VERSION "1.1"

NS_ :

BS_:
BU_:

CM_ "CZONE Proprietary MSG DBC File
Author: Dominique Parolin and some other random GUY !
for Winnebago Industries Inc.
";

CM_ "80ff0400 Used for just the PGN portion for all devices and priorities";
BO_ 2164196352 Heartbeat: 8 Vector__XXX
    SG_ Manufacturer_Code: 0|16@1+ (1,0)   [0|65535]   "ID"    Vector__XXX
    SG_ Dipswitch: 16|8@1+ (1,0)   [0|255]     "DIP"   Vector__XXX
    SG_ Instance: 24|8@1+ (1,0)   [0|255]     "?"     Vector__XXX
    SG_ Output1: 32|1@1+ (1,0)   [0|1]   "OnOff"     Vector__XXX
    SG_ Output2: 33|1@1+ (1,0)   [0|1]   "OnOff"     Vector__XXX
    SG_ Output3: 34|1@1+ (1,0)   [0|1]   "OnOff"     Vector__XXX
    SG_ Output4: 35|1@1+ (1,0)   [0|1]   "OnOff"     Vector__XXX
    SG_ Output5: 36|1@1+ (1,0)   [0|1]   "OnOff"     Vector__XXX
    SG_ Output6: 37|1@1+ (1,0)   [0|1]   "OnOff"     Vector__XXX
    SG_ Output7: 38|1@1+ (1,0)   [0|1]   "OnOff"     Vector__XXX
    SG_ Output8: 39|1@1+ (1,0)   [0|1]   "OnOff"     Vector__XXX
    SG_ Output9: 40|1@1+ (1,0)   [0|1]   "OnOff"     Vector__XXX
    SG_ Output10: 41|1@1+ (1,0)   [0|1]   "OnOff"     Vector__XXX
    SG_ Output11: 42|1@1+ (1,0)   [0|1]   "OnOff"     Vector__XXX
    SG_ Output12: 43|1@1+ (1,0)   [0|1]   "OnOff"     Vector__XXX
    SG_ Output13: 44|1@1+ (1,0)   [0|1]   "OnOff"     Vector__XXX
    SG_ Output14: 45|1@1+ (1,0)   [0|1]   "OnOff"     Vector__XXX
    SG_ Output15: 46|1@1+ (1,0)   [0|1]   "OnOff"     Vector__XXX
    SG_ Output16: 47|1@1+ (1,0)   [0|1]   "OnOff"     Vector__XXX
    SG_ Output17: 48|1@1+ (1,0)   [0|1]   "OnOff"     Vector__XXX
    SG_ Output18: 49|1@1+ (1,0)   [0|1]   "OnOff"     Vector__XXX
    SG_ Output19: 50|1@1+ (1,0)   [0|1]   "OnOff"     Vector__XXX
    SG_ Output20: 51|1@1+ (1,0)   [0|1]   "OnOff"     Vector__XXX
    SG_ Output21: 52|1@1+ (1,0)   [0|1]   "OnOff"     Vector__XXX
    SG_ Output22: 53|1@1+ (1,0)   [0|1]   "OnOff"     Vector__XXX
    SG_ Output23: 54|1@1+ (1,0)   [0|1]   "OnOff"     Vector__XXX
    SG_ Output24: 55|1@1+ (1,0)   [0|1]   "OnOff"     Vector__XXX
    SG_ Output25: 56|1@1+ (1,0)   [0|1]   "OnOff"     Vector__XXX
    SG_ Output26: 57|1@1+ (1,0)   [0|1]   "OnOff"     Vector__XXX
    SG_ Output27: 58|1@1+ (1,0)   [0|1]   "OnOff"     Vector__XXX
    SG_ Output28: 59|1@1+ (1,0)   [0|1]   "OnOff"     Vector__XXX
    SG_ Output29: 60|1@1+ (1,0)   [0|1]   "OnOff"     Vector__XXX
    SG_ Output30: 61|1@1+ (1,0)   [0|1]   "OnOff"     Vector__XXX
    SG_ Output31: 62|1@1+ (1,0)   [0|1]   "OnOff"     Vector__XXX
    SG_ Output32: 63|1@1+ (1,0)   [0|1]   "OnOff"     Vector__XXX

    39207 "BEP Marine";

CM_ "80ff1C00 Used for just the PGN portion for all devices and priorities";
BO_ 2164202496 RvSwitch: 8 Vector__XXX
    SG_ Manufacturer_Code: 0|16@1+ (1,0)   [0|65535]   "ID"    Vector__XXX
    SG_ Dipswitch: 16|8@1+ (1,0)   [0|255]     "DIP"   Vector__XXX
    SG_ Instance: 24|8@1+ (1,0)   [0|255]     "?"     Vector__XXX
    SG_ Output1: 32|1@1+ (1,0)   [0|1]   "OnOff"     Vector__XXX
    SG_ Output2: 33|1@1+ (1,0)   [0|1]   "OnOff"     Vector__XXX
    SG_ Output3: 34|1@1+ (1,0)   [0|1]   "OnOff"     Vector__XXX
    SG_ Output4: 35|1@1+ (1,0)   [0|1]   "OnOff"     Vector__XXX
    SG_ Output5: 36|1@1+ (1,0)   [0|1]   "OnOff"     Vector__XXX
    SG_ Output6: 37|1@1+ (1,0)   [0|1]   "OnOff"     Vector__XXX
    SG_ Output7: 38|1@1+ (1,0)   [0|1]   "OnOff"     Vector__XXX
    SG_ Output8: 39|1@1+ (1,0)   [0|1]   "OnOff"     Vector__XXX
    SG_ Output9: 40|1@1+ (1,0)   [0|1]   "OnOff"     Vector__XXX
    SG_ Output10: 41|1@1+ (1,0)   [0|1]   "OnOff"     Vector__XXX
    SG_ Output11: 42|1@1+ (1,0)   [0|1]   "OnOff"     Vector__XXX
    SG_ Output12:        43|1@1+ (1,0)   [0|1]   "OnOff"     Vector__XXX
    SG_ Output13:        44|1@1+ (1,0)   [0|1]   "OnOff"     Vector__XXX
    SG_ Output14:        45|1@1+ (1,0)   [0|1]   "OnOff"     Vector__XXX
    SG_ Output15:        46|1@1+ (1,0)   [0|1]   "OnOff"     Vector__XXX
    SG_ Output16:        47|1@1+ (1,0)   [0|1]   "OnOff"     Vector__XXX
    SG_ Output17:        48|1@1+ (1,0)   [0|1]   "OnOff"     Vector__XXX
    SG_ Output18:        49|1@1+ (1,0)   [0|1]   "OnOff"     Vector__XXX
    SG_ Output19:        50|1@1+ (1,0)   [0|1]   "OnOff"     Vector__XXX
    SG_ Output20:        51|1@1+ (1,0)   [0|1]   "OnOff"     Vector__XXX
    SG_ Output21:        52|1@1+ (1,0)   [0|1]   "OnOff"     Vector__XXX
    SG_ Output22:        53|1@1+ (1,0)   [0|1]   "OnOff"     Vector__XXX
    SG_ Output23:        54|1@1+ (1,0)   [0|1]   "OnOff"     Vector__XXX
    SG_ Output24:        55|1@1+ (1,0)   [0|1]   "OnOff"     Vector__XXX
    SG_ Output25:        56|1@1+ (1,0)   [0|1]   "OnOff"     Vector__XXX
    SG_ Output26:        57|1@1+ (1,0)   [0|1]   "OnOff"     Vector__XXX
    SG_ Output27:        58|1@1+ (1,0)   [0|1]   "OnOff"     Vector__XXX
    SG_ Output28:        59|1@1+ (1,0)   [0|1]   "OnOff"     Vector__XXX
    SG_ Output29:        60|1@1+  (1,0)   [0|1]   "OnOff"     Vector__XXX
    SG_ Output30:        61|1@1+ (1,0)   [0|1]   "OnOff"     Vector__XXX
    SG_ Output31:        62|1@1+ (1,0)   [0|1]   "OnOff"     Vector__XXX
    SG_ Output32:        63|1@1+ (1,0)   [0|1]   "OnOff"     Vector__XXX

CM_ "80ff1C00 Used for just the PGN portion for all devices and priorities";
    39207 "BEP Marine";

CM_ "80ff1500 ";
BO_ 2164200704 RvOutput: 8 Vector__XXX
    SG_ Manufacturer_Code:        0|16@1+ (1,0)   [0|65535]   "ID"    Vector__XXX
    SG_ Dipswitch:        16|8@1+ (1,0)   [0|255]     "DIP"   Vector__XXX
    SG_ Instance:        24|8@1+ (1,0)   [0|255]     "?"     Vector__XXX
    SG_ Output1:        32|1@1+ (1,0)   [0|1]   "OnOff"     Vector__XXX
    SG_ Output2:        33|1@1+ (1,0)   [0|1]   "OnOff"     Vector__XXX
    SG_ Output3:        34|1@1+ (1,0)   [0|1]   "OnOff"     Vector__XXX
    SG_ Output4:        35|1@1+ (1,0)   [0|1]   "OnOff"     Vector__XXX
    SG_ Output5:        36|1@1+ (1,0)   [0|1]   "OnOff"     Vector__XXX
    SG_ Output6:        37|1@1+ (1,0)   [0|1]   "OnOff"     Vector__XXX
    SG_ Output7:        38|1@1+ (1,0)   [0|1]   "OnOff"     Vector__XXX
    SG_ Output8:        39|1@1+ (1,0)   [0|1]   "OnOff"     Vector__XXX
    SG_ Output9:        40|1@1+ (1,0)   [0|1]   "OnOff"     Vector__XXX
    SG_ Output10:        41|1@1+ (1,0)   [0|1]   "OnOff"     Vector__XXX
    SG_ Output11:        42|1@1+ (1,0)   [0|1]   "OnOff"     Vector__XXX
    SG_ Output12:        43|1@1+ (1,0)   [0|1]   "OnOff"     Vector__XXX
    SG_ Output13:        44|1@1+ (1,0)   [0|1]   "OnOff"     Vector__XXX
    SG_ Output14:        45|1@1+ (1,0)   [0|1]   "OnOff"     Vector__XXX
    SG_ Output15:        46|1@1+ (1,0)   [0|1]   "OnOff"     Vector__XXX
    SG_ Output16:        47|1@1+ (1,0)   [0|1]   "OnOff"     Vector__XXX
    SG_ Output17:        48|1@1+ (1,0)   [0|1]   "OnOff"     Vector__XXX
    SG_ Output18:        49|1@1+ (1,0)   [0|1]   "OnOff"     Vector__XXX
    SG_ Output19:        50|1@1+ (1,0)   [0|1]   "OnOff"     Vector__XXX
    SG_ Output20:        51|1@1+ (1,0)   [0|1]   "OnOff"     Vector__XXX
    SG_ Output21:        52|1@1+ (1,0)   [0|1]   "OnOff"     Vector__XXX
    SG_ Output22:        53|1@1+ (1,0)   [0|1]   "OnOff"     Vector__XXX
    SG_ Output23:        54|1@1+ (1,0)   [0|1]   "OnOff"     Vector__XXX
    SG_ Output24:        55|1@1+ (1,0)   [0|1]   "OnOff"     Vector__XXX
    SG_ Output25:        56|1@1+ (1,0)   [0|1]   "OnOff"     Vector__XXX
    SG_ Output26:        57|1@1+ (1,0)   [0|1]   "OnOff"     Vector__XXX
    SG_ Output27:        58|1@1+ (1,0)   [0|1]   "OnOff"     Vector__XXX
    SG_ Output28:        59|1@1+ (1,0)   [0|1]   "OnOff"     Vector__XXX
    SG_ Output29:        60|1@1+  (1,0)   [0|1]   "OnOff"     Vector__XXX
    SG_ Output30:        61|1@1+ (1,0)   [0|1]   "OnOff"     Vector__XXX
    SG_ Output31:        62|1@1+ (1,0)   [0|1]   "OnOff"     Vector__XXX
    SG_ Output32:        63|1@1+ (1,0)   [0|1]   "OnOff"     Vector__XXX

CM_ "ff1500 Used for just the PGN portion for all devices and priorities";
    39207 "BEP Marine";

CM_ "ff0f00 Czone Alerts";
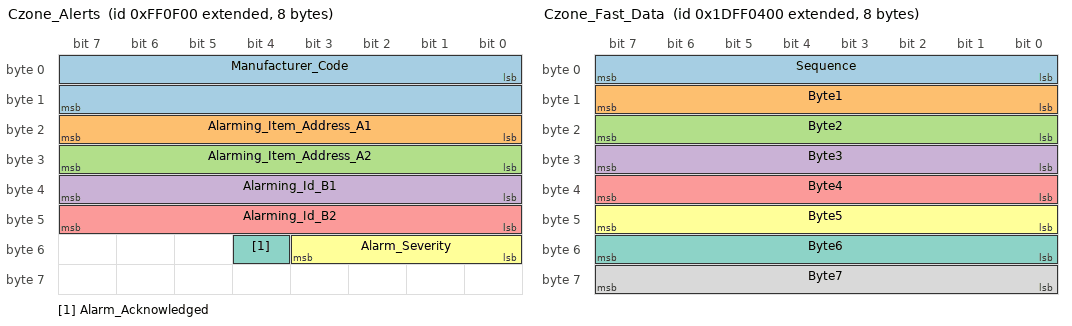
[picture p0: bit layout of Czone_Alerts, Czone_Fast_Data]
BO_ 2164199168 Czone_Alerts: 8 Vector__XXX
    SG_ Manufacturer_Code:        0|16@1+ (1,0)   [0|65535]   "ID"    Vector__XXX
    SG_ Alarming_Item_Address_A1:        16|8@1+ (1,0)   [0|255]     "#"     Vector__XXX
    SG_ Alarming_Item_Address_A2:        24|8@1+ (1,0)   [0|255]     "#"     Vector__XXX
    SG_ Alarming_Id_B1:        32|8@1+ (1,0)   [0|255]     "#"     Vector__XXX
    SG_ Alarming_Id_B2:        40|8@1+ (1,0)   [0|255]     "#"     Vector__XXX
    SG_ Alarm_Severity:     48|4@1+ (1,0)   [0|16]  ""  Vector__XXX
    SG_ Alarm_Acknowledged:     52|1@1+ (1,0)   [0|16]  ""  Vector__XXX

VAL_ 2164199168 Manufacturer_Code 39207 "BEP Marine";
    0 "None"
    1 "Critical"
    2 "Important"
    3 "Standard"
    4 "Warning"
    5 "Systems-On";

CM_ "1Dff0400 Czone Fast Data";
BO_ 2650735616 Czone_Fast_Data: 8 Vector__XXX
    SG_ Sequence:     0|8@1+  (1,0)   [0|255]     "#"    Vector__XXX
    SG_ Byte1:        8|8@1+  (1,0)   [0|255]     ""     Vector__XXX
    SG_ Byte2:        16|8@1+ (1,0)   [0|255]     ""     Vector__XXX
    SG_ Byte3:        24|8@1+ (1,0)   [0|255]     ""     Vector__XXX
    SG_ Byte4:        32|8@1+ (1,0)   [0|255]     ""     Vector__XXX
    SG_ Byte5:        40|8@1+ (1,0)   [0|255]     ""     Vector__XXX
    SG_ Byte6:        48|8@1+ (1,0)   [0|255]     ""     Vector__XXX
    SG_ Byte7:        56|8@1+ (1,0)   [0|255]     ""     Vector__XXX

CM_ "1Dff0400 Czone Fast Data";
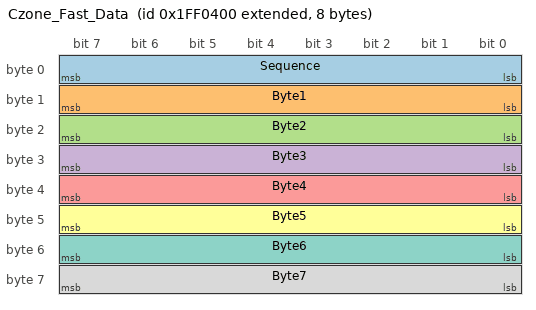
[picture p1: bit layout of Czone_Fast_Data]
BO_ 2180973568 Czone_Fast_Data: 8 Vector__XXX
    SG_ Sequence:     0|8@1+  (1,0)   [0|255]     "#"    Vector__XXX
    SG_ Byte1:        8|8@1+  (1,0)   [0|255]     ""     Vector__XXX
    SG_ Byte2:        16|8@1+ (1,0)   [0|255]     ""     Vector__XXX
    SG_ Byte3:        24|8@1+ (1,0)   [0|255]     ""     Vector__XXX
    SG_ Byte4:        32|8@1+ (1,0)   [0|255]     ""     Vector__XXX
    SG_ Byte5:        40|8@1+ (1,0)   [0|255]     ""     Vector__XXX
    SG_ Byte6:        48|8@1+ (1,0)   [0|255]     ""     Vector__XXX
    SG_ Byte7:        56|8@1+ (1,0)   [0|255]     ""     Vector__XXX
